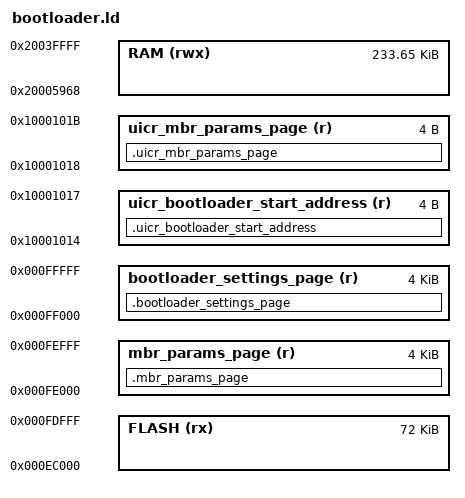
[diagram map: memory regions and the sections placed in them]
/* Linker script to configure memory regions. */

SEARCH_DIR(.)
GROUP(-lgcc -lc -lnosys)

MEMORY
{
  FLASH (rx) : ORIGIN = 0xec000, LENGTH = 0x12000
  RAM (rwx) :  ORIGIN = 0x20005968, LENGTH = 0x3a698
  uicr_bootloader_start_address (r) : ORIGIN = 0x10001014, LENGTH = 0x4
  bootloader_settings_page (r) : ORIGIN = 0x000FF000, LENGTH = 0x1000
  uicr_mbr_params_page (r) : ORIGIN = 0x10001018, LENGTH = 0x4
  mbr_params_page (r) : ORIGIN = 0x000FE000, LENGTH = 0x1000
}

SECTIONS
{
  .uicr_bootloader_start_address :
  {
    PROVIDE(__start_uicr_bootloader_start_address = .);
    KEEP(*(SORT(.uicr_bootloader_start_address*)))
    PROVIDE(__stop_uicr_bootloader_start_address = .);
  } > uicr_bootloader_start_address
  .uicr_mbr_params_page :
  {
    PROVIDE(__start_uicr_mbr_params_page = .);
    KEEP(*(SORT(.uicr_mbr_params_page*)))
    PROVIDE(__stop_uicr_mbr_params_page = .);
  } > uicr_mbr_params_page
  .mbr_params_page(NOLOAD) :
  {
    PROVIDE(__start_mbr_params_page = .);
    KEEP(*(SORT(.mbr_params_page*)))
    PROVIDE(__stop_mbr_params_page = .);
  } > mbr_params_page
  .bootloader_settings_page(NOLOAD) :
  {
    PROVIDE(__start_bootloader_settings_page = .);
    KEEP(*(SORT(.bootloader_settings_page*)))
    PROVIDE(__stop_bootloader_settings_page = .);
  } > bootloader_settings_page
}

INCLUDE "nrf52.ld"
